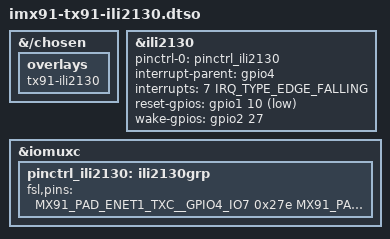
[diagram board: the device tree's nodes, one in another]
// SPDX-License-Identifier: (GPL-2.0 OR MIT)
/*
 * Copyright 2023 Lothar Waßmann <LW@KARO-electronics.de>
 *
 */

/dts-v1/;

/plugin/;

#include <dt-bindings/gpio/gpio.h>
#include <dt-bindings/interrupt-controller/irq.h>
#include "includes/imx91-karo-ili2130.dtsi"
#include "imx91-pinfunc.h"

&{/chosen} {
	overlays {
		tx91-ili2130;
	};
};

&ili2130 {
	pinctrl-names = "default";
	pinctrl-0 = <&pinctrl_ili2130>;
	interrupt-parent = <&gpio4>;
	interrupts = <7 IRQ_TYPE_EDGE_FALLING>;
	reset-gpios = <&gpio1 10 GPIO_ACTIVE_LOW>;
	wake-gpios = <&gpio2 27 GPIO_ACTIVE_HIGH>;
};

&iomuxc {
	pinctrl_ili2130: ili2130grp {
		fsl,pins = <
			    MX91_PAD_ENET1_TXC__GPIO4_IO7		0x27e /* Interrupt */
			    MX91_PAD_PDM_BIT_STREAM1__GPIO1_IO10	0x27e /* Reset */
			    MX91_PAD_GPIO_IO27__GPIO2_IO27		0x27e /* Wake */
		>;
	};
};
